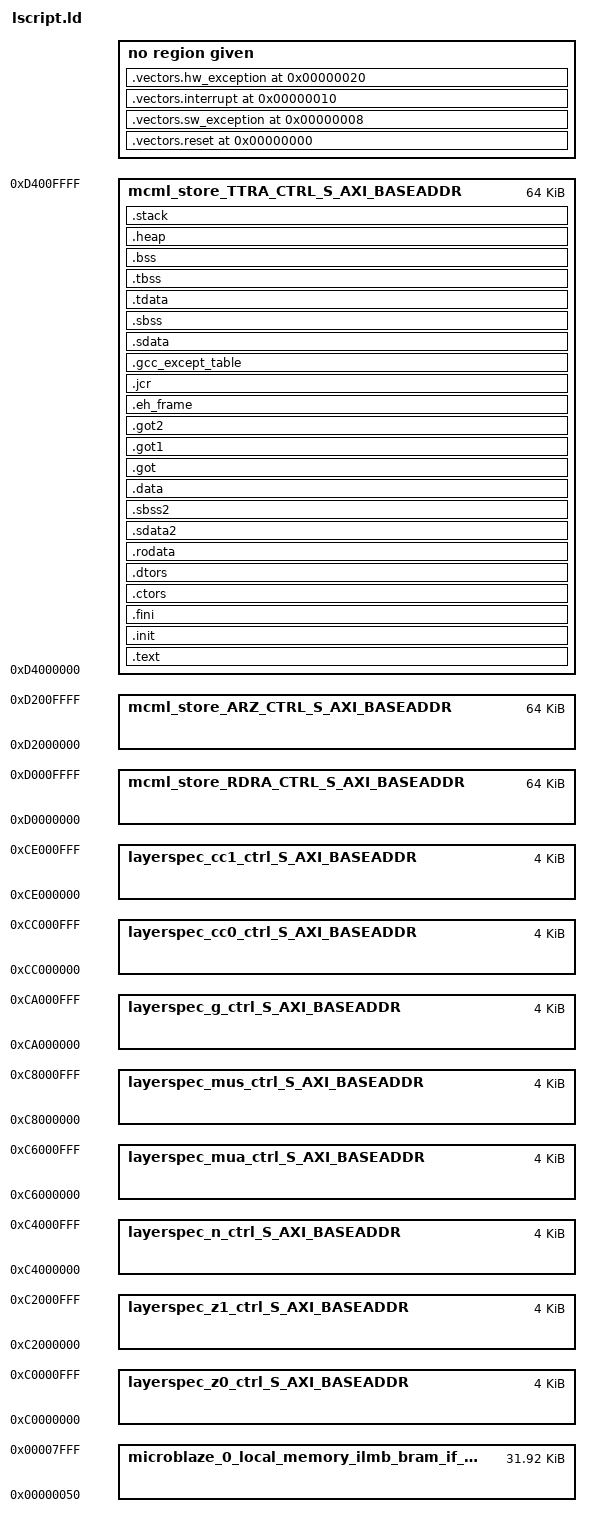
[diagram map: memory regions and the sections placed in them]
/*******************************************************************/
/*                                                                 */
/* This file is automatically generated by linker script generator.*/
/*                                                                 */
/* Version:                                 */
/*                                                                 */
/* Copyright (c) 2010 Xilinx, Inc.  All rights reserved.           */
/*                                                                 */
/* Description : MicroBlaze Linker Script                          */
/*                                                                 */
/*******************************************************************/

_STACK_SIZE = DEFINED(_STACK_SIZE) ? _STACK_SIZE : 0x400;
_HEAP_SIZE = DEFINED(_HEAP_SIZE) ? _HEAP_SIZE : 0x800;

/* Define Memories in the system */

MEMORY
{
   microblaze_0_local_memory_ilmb_bram_if_cntlr_microblaze_0_local_memory_dlmb_bram_if_cntlr : ORIGIN = 0x50, LENGTH = 0x7FB0
   layerspec_z0_ctrl_S_AXI_BASEADDR : ORIGIN = 0xC0000000, LENGTH = 0x1000
   layerspec_z1_ctrl_S_AXI_BASEADDR : ORIGIN = 0xC2000000, LENGTH = 0x1000
   layerspec_n_ctrl_S_AXI_BASEADDR : ORIGIN = 0xC4000000, LENGTH = 0x1000
   layerspec_mua_ctrl_S_AXI_BASEADDR : ORIGIN = 0xC6000000, LENGTH = 0x1000
   layerspec_mus_ctrl_S_AXI_BASEADDR : ORIGIN = 0xC8000000, LENGTH = 0x1000
   layerspec_g_ctrl_S_AXI_BASEADDR : ORIGIN = 0xCA000000, LENGTH = 0x1000
   layerspec_cc0_ctrl_S_AXI_BASEADDR : ORIGIN = 0xCC000000, LENGTH = 0x1000
   layerspec_cc1_ctrl_S_AXI_BASEADDR : ORIGIN = 0xCE000000, LENGTH = 0x1000
   mcml_store_RDRA_CTRL_S_AXI_BASEADDR : ORIGIN = 0xD0000000, LENGTH = 0x10000
   mcml_store_ARZ_CTRL_S_AXI_BASEADDR : ORIGIN = 0xD2000000, LENGTH = 0x10000
   mcml_store_TTRA_CTRL_S_AXI_BASEADDR : ORIGIN = 0xD4000000, LENGTH = 0x10000
}

/* Specify the default entry point to the program */

ENTRY(_start)

/* Define the sections, and where they are mapped in memory */

SECTIONS
{
.vectors.reset 0x0 : {
   KEEP (*(.vectors.reset))
} 

.vectors.sw_exception 0x8 : {
   KEEP (*(.vectors.sw_exception))
} 

.vectors.interrupt 0x10 : {
   KEEP (*(.vectors.interrupt))
} 

.vectors.hw_exception 0x20 : {
   KEEP (*(.vectors.hw_exception))
} 

.text : {
   *(.text)
   *(.text.*)
   *(.gnu.linkonce.t.*)
} > mcml_store_TTRA_CTRL_S_AXI_BASEADDR

.init : {
   KEEP (*(.init))
} > mcml_store_TTRA_CTRL_S_AXI_BASEADDR

.fini : {
   KEEP (*(.fini))
} > mcml_store_TTRA_CTRL_S_AXI_BASEADDR

.ctors : {
   __CTOR_LIST__ = .;
   ___CTORS_LIST___ = .;
   KEEP (*crtbegin.o(.ctors))
   KEEP (*(EXCLUDE_FILE(*crtend.o) .ctors))
   KEEP (*(SORT(.ctors.*)))
   KEEP (*(.ctors))
   __CTOR_END__ = .;
   ___CTORS_END___ = .;
} > mcml_store_TTRA_CTRL_S_AXI_BASEADDR

.dtors : {
   __DTOR_LIST__ = .;
   ___DTORS_LIST___ = .;
   KEEP (*crtbegin.o(.dtors))
   KEEP (*(EXCLUDE_FILE(*crtend.o) .dtors))
   KEEP (*(SORT(.dtors.*)))
   KEEP (*(.dtors))
   PROVIDE(__DTOR_END__ = .);
   PROVIDE(___DTORS_END___ = .);
} > mcml_store_TTRA_CTRL_S_AXI_BASEADDR

.rodata : {
   __rodata_start = .;
   *(.rodata)
   *(.rodata.*)
   *(.gnu.linkonce.r.*)
   __rodata_end = .;
} > mcml_store_TTRA_CTRL_S_AXI_BASEADDR

.sdata2 : {
   . = ALIGN(8);
   __sdata2_start = .;
   *(.sdata2)
   *(.sdata2.*)
   *(.gnu.linkonce.s2.*)
   . = ALIGN(8);
   __sdata2_end = .;
} > mcml_store_TTRA_CTRL_S_AXI_BASEADDR

.sbss2 : {
   __sbss2_start = .;
   *(.sbss2)
   *(.sbss2.*)
   *(.gnu.linkonce.sb2.*)
   __sbss2_end = .;
} > mcml_store_TTRA_CTRL_S_AXI_BASEADDR

.data : {
   . = ALIGN(4);
   __data_start = .;
   *(.data)
   *(.data.*)
   *(.gnu.linkonce.d.*)
   __data_end = .;
} > mcml_store_TTRA_CTRL_S_AXI_BASEADDR

.got : {
   *(.got)
} > mcml_store_TTRA_CTRL_S_AXI_BASEADDR

.got1 : {
   *(.got1)
} > mcml_store_TTRA_CTRL_S_AXI_BASEADDR

.got2 : {
   *(.got2)
} > mcml_store_TTRA_CTRL_S_AXI_BASEADDR

.eh_frame : {
   *(.eh_frame)
} > mcml_store_TTRA_CTRL_S_AXI_BASEADDR

.jcr : {
   *(.jcr)
} > mcml_store_TTRA_CTRL_S_AXI_BASEADDR

.gcc_except_table : {
   *(.gcc_except_table)
} > mcml_store_TTRA_CTRL_S_AXI_BASEADDR

.sdata : {
   . = ALIGN(8);
   __sdata_start = .;
   *(.sdata)
   *(.sdata.*)
   *(.gnu.linkonce.s.*)
   __sdata_end = .;
} > mcml_store_TTRA_CTRL_S_AXI_BASEADDR

.sbss (NOLOAD) : {
   . = ALIGN(4);
   __sbss_start = .;
   *(.sbss)
   *(.sbss.*)
   *(.gnu.linkonce.sb.*)
   . = ALIGN(8);
   __sbss_end = .;
} > mcml_store_TTRA_CTRL_S_AXI_BASEADDR

.tdata : {
   __tdata_start = .;
   *(.tdata)
   *(.tdata.*)
   *(.gnu.linkonce.td.*)
   __tdata_end = .;
} > mcml_store_TTRA_CTRL_S_AXI_BASEADDR

.tbss : {
   __tbss_start = .;
   *(.tbss)
   *(.tbss.*)
   *(.gnu.linkonce.tb.*)
   __tbss_end = .;
} > mcml_store_TTRA_CTRL_S_AXI_BASEADDR

.bss (NOLOAD) : {
   . = ALIGN(4);
   __bss_start = .;
   *(.bss)
   *(.bss.*)
   *(.gnu.linkonce.b.*)
   *(COMMON)
   . = ALIGN(4);
   __bss_end = .;
} > mcml_store_TTRA_CTRL_S_AXI_BASEADDR

_SDA_BASE_ = __sdata_start + ((__sbss_end - __sdata_start) / 2 );

_SDA2_BASE_ = __sdata2_start + ((__sbss2_end - __sdata2_start) / 2 );

/* Generate Stack and Heap definitions */

.heap (NOLOAD) : {
   . = ALIGN(8);
   _heap = .;
   _heap_start = .;
   . += _HEAP_SIZE;
   _heap_end = .;
} > mcml_store_TTRA_CTRL_S_AXI_BASEADDR

.stack (NOLOAD) : {
   _stack_end = .;
   . += _STACK_SIZE;
   . = ALIGN(8);
   _stack = .;
   __stack = _stack;
} > mcml_store_TTRA_CTRL_S_AXI_BASEADDR

_end = .;
}

